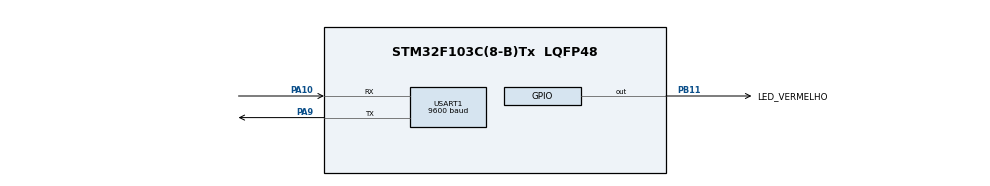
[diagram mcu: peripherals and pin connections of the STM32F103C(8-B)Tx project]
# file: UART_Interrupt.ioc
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Mcu.Family=STM32F1
RCC.APB2Freq_Value=8000000
PA10.Mode=Asynchronous
USART1.BaudRate=9600
PB11.GPIO_Label=LED_VERMELHO
Mcu.Name=STM32F103C(8-B)Tx
PB11.Signal=GPIO_Output
VP_SYS_VS_ND.Mode=No_Debug
Mcu.Package=LQFP48
ProjectManager.StackSize=0x400
USART1.VirtualMode=VM_ASYNC
PA9.Mode=Asynchronous
PA10.Signal=USART1_RX
ProjectManager.HeapSize=0x200
ProjectManager.TargetToolchain=STM32CubeIDE
NVIC.PriorityGroup=NVIC_PRIORITYGROUP_4
PA9.Signal=USART1_TX
NVIC.USART1_IRQn=true\:0\:0\:false\:false\:true\:true\:true
RCC.APB1Freq_Value=8000000
board=custom

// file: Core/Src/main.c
/* USER CODE BEGIN Header */
/**
  ******************************************************************************
  * @file           : main.c
  * @brief          : Main program body
  ******************************************************************************
  * @attention
  *
  * <h2><center>&copy; Copyright (c) 2021 STMicroelectronics.
  * All rights reserved.</center></h2>
  *
  * This software component is licensed by ST under BSD 3-Clause license,
  * the "License"; You may not use this file except in compliance with the
  * License. You may obtain a copy of the License at:
  *                        opensource.org/licenses/BSD-3-Clause
  *
  ******************************************************************************
  */
/* USER CODE END Header */
#include "main.h"

/* USER CODE BEGIN Includes */
#include<string.h>
#include<stdio.h>
/* USER CODE END Includes */

UART_HandleTypeDef huart1;

void SystemClock_Config(void);
static void MX_GPIO_Init(void);
static void MX_USART1_UART_Init(void);

// comando a ser enviado para serial, 0 Apaga o Led e 1 Acende o Led
uint8_t DadoRX = 0;

// guarda o estado do Led, 0 apagado, 1 aceso
uint8_t DadoTX[1] = {0};

// variável para decidir se deve ser escrito o estado do Led
uint8_t flag = 0;

// quando acabar o recebimento do dado que está sendo transmitido pela UART
// a função HAL_UART_RxCpltCallback será chamada e depois irá retornar
// o controle ao programa principal
void HAL_UART_RxCpltCallback(UART_HandleTypeDef *huart1)
{
	// se o usuário digitar o caractere 1 (0x31) e o LED estiver apagado, o LED irá acender
	if (DadoRX == 0X31 && !HAL_GPIO_ReadPin(LED_VERMELHO_GPIO_Port, LED_VERMELHO_Pin))
	{
		HAL_GPIO_TogglePin(LED_VERMELHO_GPIO_Port, LED_VERMELHO_Pin);
		flag = 0;
	}
	// se o usuário digitar o caractere 0 (0x30) e o LED estiver aceso, o LED irá apagar
	else if (DadoRX == 0X30 && HAL_GPIO_ReadPin(LED_VERMELHO_GPIO_Port, LED_VERMELHO_Pin))
	{
		HAL_GPIO_TogglePin(LED_VERMELHO_GPIO_Port, LED_VERMELHO_Pin);
		flag = 0;
	}
	else
		flag = 1;

	// se o usuário mandar algum comando para a UART o valor da flag permanece em 0 e será
	// impresso o estado do LED
	if (!flag)
	{
		// Atualiza a tela do terminal com o estado do led
		// Quando a leitura da função HAL_GPIO_ReadPin for 1, DadoTX guardará o valor '1'
		// quando for 0, DadoTX guardará o valor '0'
		if (HAL_GPIO_ReadPin(LED_VERMELHO_GPIO_Port, LED_VERMELHO_Pin) == GPIO_PIN_SET)
			DadoTX[1] = '1';
		else
			DadoTX[1] = '0';

		// Envia pela serial texto atualizado
		HAL_UART_Transmit(huart1, DadoTX, 2, 500);
	}
}

int main(void)
{

  /* MCU Configuration--------------------------------------------------------*/

  /* Reset of all peripherals, Initializes the Flash interface and the Systick. */
  HAL_Init();

  /* Configure the system clock */
  SystemClock_Config();

  /* Initialize all configured peripherals */
  MX_GPIO_Init();
  MX_USART1_UART_Init();

  /* Infinite loop */
  /* USER CODE BEGIN WHILE */

  while (1)
  {
	// recebe dados pela UART
	HAL_UART_Receive_IT(&huart1, &DadoRX, 1);

	/* USER CODE END WHILE */

  }
}

void SystemClock_Config(void)
{
  RCC_OscInitTypeDef RCC_OscInitStruct = {0};
  RCC_ClkInitTypeDef RCC_ClkInitStruct = {0};

  /** Initializes the RCC Oscillators according to the specified parameters
  * in the RCC_OscInitTypeDef structure.
  */
  RCC_OscInitStruct.OscillatorType = RCC_OSCILLATORTYPE_HSI;
  RCC_OscInitStruct.HSIState = RCC_HSI_ON;
  RCC_OscInitStruct.HSICalibrationValue = RCC_HSICALIBRATION_DEFAULT;
  RCC_OscInitStruct.PLL.PLLState = RCC_PLL_NONE;
  if (HAL_RCC_OscConfig(&RCC_OscInitStruct) != HAL_OK)
  {
    Error_Handler();
  }
  /** Initializes the CPU, AHB and APB buses clocks
  */
  RCC_ClkInitStruct.ClockType = RCC_CLOCKTYPE_HCLK|RCC_CLOCKTYPE_SYSCLK
                              |RCC_CLOCKTYPE_PCLK1|RCC_CLOCKTYPE_PCLK2;
  RCC_ClkInitStruct.SYSCLKSource = RCC_SYSCLKSOURCE_HSI;
  RCC_ClkInitStruct.AHBCLKDivider = RCC_SYSCLK_DIV1;
  RCC_ClkInitStruct.APB1CLKDivider = RCC_HCLK_DIV1;
  RCC_ClkInitStruct.APB2CLKDivider = RCC_HCLK_DIV1;

  if (HAL_RCC_ClockConfig(&RCC_ClkInitStruct, FLASH_LATENCY_0) != HAL_OK)
  {
    Error_Handler();
  }
}

static void MX_USART1_UART_Init(void)
{

  huart1.Instance = USART1;
  huart1.Init.BaudRate = 9600;
  huart1.Init.WordLength = UART_WORDLENGTH_8B;
  huart1.Init.StopBits = UART_STOPBITS_1;
  huart1.Init.Parity = UART_PARITY_NONE;
  huart1.Init.Mode = UART_MODE_TX_RX;
  huart1.Init.HwFlowCtl = UART_HWCONTROL_NONE;
  huart1.Init.OverSampling = UART_OVERSAMPLING_16;
  if (HAL_UART_Init(&huart1) != HAL_OK)
  {
    Error_Handler();
  }

}

static void MX_GPIO_Init(void)
{
  GPIO_InitTypeDef GPIO_InitStruct = {0};

  /* GPIO Ports Clock Enable */
  __HAL_RCC_GPIOB_CLK_ENABLE();
  __HAL_RCC_GPIOA_CLK_ENABLE();

  /*Configure GPIO pin Output Level */
  HAL_GPIO_WritePin(LED_VERMELHO_GPIO_Port, LED_VERMELHO_Pin, GPIO_PIN_RESET);

  /*Configure GPIO pin : LED_VERMELHO_Pin */
  GPIO_InitStruct.Pin = LED_VERMELHO_Pin;
  GPIO_InitStruct.Mode = GPIO_MODE_OUTPUT_PP;
  GPIO_InitStruct.Pull = GPIO_NOPULL;
  GPIO_InitStruct.Speed = GPIO_SPEED_FREQ_LOW;
  HAL_GPIO_Init(LED_VERMELHO_GPIO_Port, &GPIO_InitStruct);

}

void Error_Handler(void)
{
  __disable_irq();
  while (1)
  {
  }
}

/************************ (C) COPYRIGHT STMicroelectronics *****END OF FILE****/
